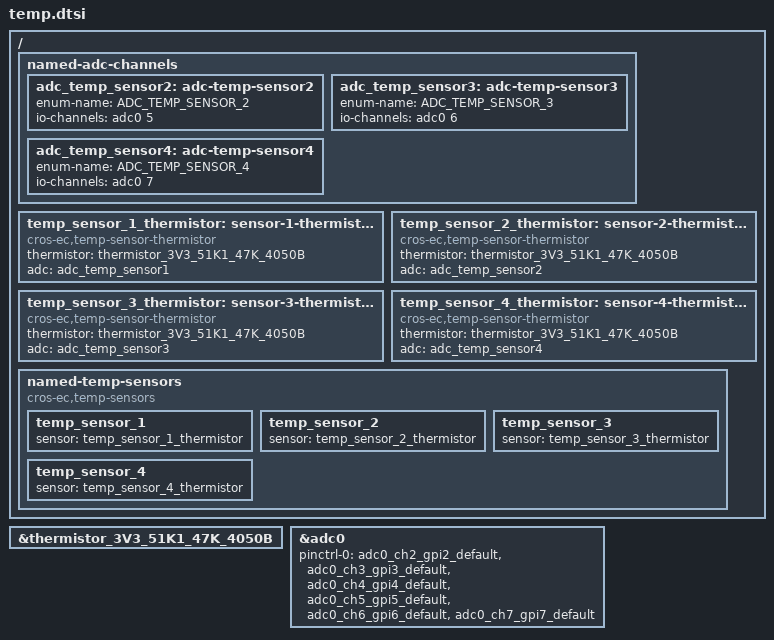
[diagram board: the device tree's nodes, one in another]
/* Copyright 2024 The ChromiumOS Authors
 * Use of this source code is governed by a BSD-style license that can be
 * found in the LICENSE file.
 */

#include <cros/thermistor/thermistor.dtsi>

/ {
	named-adc-channels {
		/delete-node/ ec_usb_c0_vbus_sense;
		/delete-node/ ec_usb_c1_vbus_sense;

		adc_temp_sensor2: adc-temp-sensor2 {
			enum-name = "ADC_TEMP_SENSOR_2";
			io-channels = <&adc0 5>;
		};
		adc_temp_sensor3: adc-temp-sensor3 {
			enum-name = "ADC_TEMP_SENSOR_3";
			io-channels = <&adc0 6>;
		};
		adc_temp_sensor4: adc-temp-sensor4 {
			enum-name = "ADC_TEMP_SENSOR_4";
			io-channels = <&adc0 7>;
		};
	};

	temp_sensor_1_thermistor: sensor-1-thermistor {
		compatible = "cros-ec,temp-sensor-thermistor";
		thermistor = <&thermistor_3V3_51K1_47K_4050B>;
		adc = <&adc_temp_sensor1>;
	};
	temp_sensor_2_thermistor: sensor-2-thermistor {
		compatible = "cros-ec,temp-sensor-thermistor";
		thermistor = <&thermistor_3V3_51K1_47K_4050B>;
		adc = <&adc_temp_sensor2>;
	};
	temp_sensor_3_thermistor: sensor-3-thermistor {
		compatible = "cros-ec,temp-sensor-thermistor";
		thermistor = <&thermistor_3V3_51K1_47K_4050B>;
		adc = <&adc_temp_sensor3>;
	};
	temp_sensor_4_thermistor: sensor-4-thermistor {
		compatible = "cros-ec,temp-sensor-thermistor";
		thermistor = <&thermistor_3V3_51K1_47K_4050B>;
		adc = <&adc_temp_sensor4>;
	};

	named-temp-sensors {
		compatible = "cros-ec,temp-sensors";
		temp_sensor_1 {
			sensor = <&temp_sensor_1_thermistor>;
		};
		temp_sensor_2: temp_sensor_2 {
			sensor = <&temp_sensor_2_thermistor>;
		};
		temp_sensor_3 {
			sensor = <&temp_sensor_3_thermistor>;
		};
		temp_sensor_4 {
			sensor = <&temp_sensor_4_thermistor>;
		};
	};
};

&thermistor_3V3_51K1_47K_4050B {
	status = "okay";
};

/* adc0 overrides */
&adc0 {
	status = "okay";
	pinctrl-0 = <&adc0_ch2_gpi2_default
		&adc0_ch3_gpi3_default
		&adc0_ch4_gpi4_default
		&adc0_ch5_gpi5_default
		&adc0_ch6_gpi6_default
		&adc0_ch7_gpi7_default>;
	pinctrl-names = "default";
};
